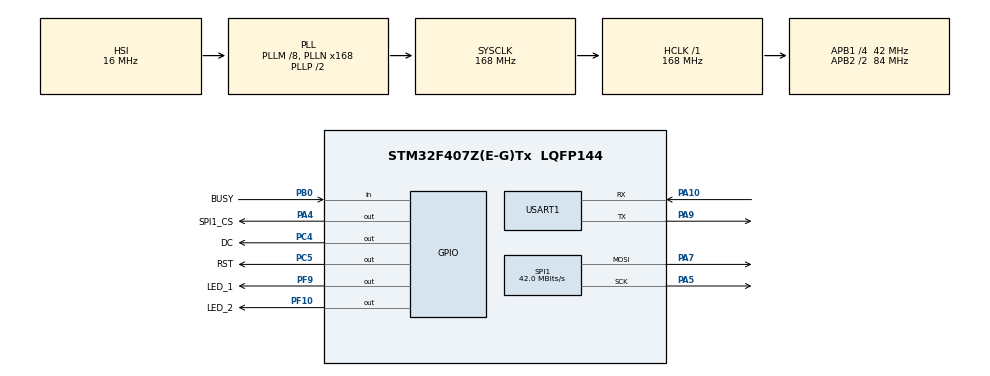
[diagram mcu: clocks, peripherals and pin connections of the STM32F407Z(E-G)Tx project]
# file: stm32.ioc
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Mcu.Family=STM32F4
Mcu.Name=STM32F407Z(E-G)Tx
Mcu.Package=LQFP144
NVIC.PriorityGroup=NVIC_PRIORITYGROUP_4
PA10.Mode=Asynchronous
PA10.Signal=USART1_RX
PA13.Mode=Serial_Wire
PA13.Signal=SYS_JTMS-SWDIO
PA14.Mode=Serial_Wire
PA14.Signal=SYS_JTCK-SWCLK
PA4.GPIO_Label=SPI1_CS
PA4.GPIO_PuPd=GPIO_PULLDOWN
PA4.GPIO_Speed=GPIO_SPEED_FREQ_VERY_HIGH
PA4.Signal=GPIO_Output
PA5.Mode=TX_Only_Simplex_Unidirect_Master
PA5.Signal=SPI1_SCK
PA7.Mode=TX_Only_Simplex_Unidirect_Master
PA7.Signal=SPI1_MOSI
PA9.Mode=Asynchronous
PA9.Signal=USART1_TX
PB0.GPIO_Label=BUSY
PB0.Signal=GPIO_Input
PC14-OSC32_IN.Mode=LSE-External-Oscillator
PC14-OSC32_IN.Signal=RCC_OSC32_IN
PC15-OSC32_OUT.Mode=LSE-External-Oscillator
PC15-OSC32_OUT.Signal=RCC_OSC32_OUT
PC4.GPIO_Label=DC
PC4.GPIO_Speed=GPIO_SPEED_FREQ_VERY_HIGH
PC4.Signal=GPIO_Output
PC5.GPIO_Label=RST
PC5.GPIO_PuPd=GPIO_PULLUP
PC5.GPIO_Speed=GPIO_SPEED_FREQ_VERY_HIGH
PC5.Signal=GPIO_Output
PF10.GPIO_Label=LED_2
PF10.GPIO_PuPd=GPIO_NOPULL
PF10.GPIO_Speed=GPIO_SPEED_FREQ_LOW
PF10.PinState=GPIO_PIN_SET
PF10.Signal=GPIO_Output
PF9.GPIO_Label=LED_1
PF9.GPIO_PuPd=GPIO_NOPULL
PF9.GPIO_Speed=GPIO_SPEED_FREQ_LOW
PF9.Signal=GPIO_Output
PH0-OSC_IN.Mode=HSE-External-Oscillator
PH0-OSC_IN.Signal=RCC_OSC_IN
PH1-OSC_OUT.Mode=HSE-External-Oscillator
PH1-OSC_OUT.Signal=RCC_OSC_OUT
ProjectManager.HeapSize=0x9000
ProjectManager.StackSize=0x1000
ProjectManager.TargetToolchain=EWARM V8.32
RCC.48MHZClocksFreq_Value=84000000
RCC.AHBFreq_Value=168000000
RCC.APB1CLKDivider=RCC_HCLK_DIV4
RCC.APB1Freq_Value=42000000
RCC.APB1TimFreq_Value=84000000
RCC.APB2CLKDivider=RCC_HCLK_DIV2
RCC.APB2Freq_Value=84000000
RCC.APB2TimFreq_Value=168000000
RCC.CortexFreq_Value=168000000
RCC.HCLKFreq_Value=168000000
RCC.HSE_VALUE=8000000
RCC.HSI_VALUE=16000000
RCC.PLLM=8
RCC.PLLN=168
RCC.SYSCLKFreq_VALUE=168000000
RCC.SYSCLKSource=RCC_SYSCLKSOURCE_PLLCLK
RCC.VCOOutputFreq_Value=336000000
SPI1.CalculateBaudRate=42.0 MBits/s
SPI1.Direction=SPI_DIRECTION_2LINES
SPI1.Mode=SPI_MODE_MASTER
SPI1.VirtualType=VM_MASTER
USART1.VirtualMode=VM_ASYNC
board=custom

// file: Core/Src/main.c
/* USER CODE BEGIN Header */
/**
  ******************************************************************************
  * @file           : main.c
  * @brief          : Main program body
  ******************************************************************************
  * @attention
  *
  * Copyright (c) 2023 STMicroelectronics.
  * All rights reserved.
  *
  * This software is licensed under terms that can be found in the LICENSE file
  * in the root directory of this software component.
  * If no LICENSE file comes with this software, it is provided AS-IS.
  *
  ******************************************************************************
  */
/* USER CODE END Header */
#include "main.h"
#include "spi.h"
#include "usart.h"
#include "gpio.h"

/* USER CODE BEGIN Includes */
#include "stdio.h"
#include "EPD_Test.h"
/* USER CODE END Includes */

void SystemClock_Config(void);

int main(void)
{

  /* MCU Configuration--------------------------------------------------------*/

  /* Reset of all peripherals, Initializes the Flash interface and the Systick. */
  HAL_Init();

  /* Configure the system clock */
  SystemClock_Config();

  /* Initialize all configured peripherals */
  MX_GPIO_Init();
  MX_SPI1_Init();
  MX_USART1_UART_Init();
  /* USER CODE BEGIN 2 */

  //EPD_1in02d_test();
  EPD_1in54_test();
  //EPD_1in54_V2_test();
  //EPD_1in54b_test();
  //EPD_1in54b_V2_test();
  //EPD_1in54c_test();
  //EPD_1in64g_test();
  //EPD_2in7_test();
  //EPD_2in7_V2_test();
  //EPD_2IN7b_test();
  //EPD_2in7b_V2_test();
  //EPD_2in9_test();
  //EPD_2in9_V2_test();
  //EPD_2IN9B_V3_test();
  //EPD_2IN9BC_test();
  //EPD_2in9d_test();
  //EPD_2in13_test();
  //EPD_2IN13_V2_test();
  //EPD_2in13_V3_test();
  //EPD_2IN13B_V3_test();
  //EPD_2in13b_V4_test();
  //EPD_2IN13BC_test();
  //EPD_2in13d_test();
  //EPD_2in36g_test();
  //EPD_2in66_test();
  //EPD_2in66b_test();
  //EPD_3in0g_test();
  //EPD_3in7_test();
  //EPD_3in52_test();
  //EPD_4IN01F_test();
  //EPD_4in2_test();
  //EPD_4in2b_V2_test();
  //EPD_4in2bc_test();
  //EPD_4in37g_test();
  //EPD_5in65f_test();
  //EPD_5in83_test();
  //EPD_5in83_V2_test();
  //EPD_5in83b_V2_test();
  //EPD_5in83bc_test();
  //EPD_7in3f_test();
  //EPD_7in3g_test();
  //EPD_7in5_HD_test();
  //EPD_7in5_test();
  //EPD_7in5_V2_test();
  //EPD_7in5b_HD_test();
  //EPD_7in5b_V2_test();
  //EPD_7in5bc_test();

  /* USER CODE END 2 */

  /* Infinite loop */
  /* USER CODE BEGIN WHILE */

  while (1)
  {
    HAL_Delay(10000);
    /* USER CODE END WHILE */

  }
}

void SystemClock_Config(void)
{
  RCC_OscInitTypeDef RCC_OscInitStruct = {0};
  RCC_ClkInitTypeDef RCC_ClkInitStruct = {0};

  /** Configure the main internal regulator output voltage
  */
  __HAL_RCC_PWR_CLK_ENABLE();
  __HAL_PWR_VOLTAGESCALING_CONFIG(PWR_REGULATOR_VOLTAGE_SCALE1);

  /** Initializes the RCC Oscillators according to the specified parameters
  * in the RCC_OscInitTypeDef structure.
  */
  RCC_OscInitStruct.OscillatorType = RCC_OSCILLATORTYPE_HSI;
  RCC_OscInitStruct.HSIState = RCC_HSI_ON;
  RCC_OscInitStruct.HSICalibrationValue = RCC_HSICALIBRATION_DEFAULT;
  RCC_OscInitStruct.PLL.PLLState = RCC_PLL_ON;
  RCC_OscInitStruct.PLL.PLLSource = RCC_PLLSOURCE_HSI;
  RCC_OscInitStruct.PLL.PLLM = 8;
  RCC_OscInitStruct.PLL.PLLN = 168;
  RCC_OscInitStruct.PLL.PLLP = RCC_PLLP_DIV2;
  RCC_OscInitStruct.PLL.PLLQ = 4;
  if (HAL_RCC_OscConfig(&RCC_OscInitStruct) != HAL_OK)
  {
    Error_Handler();
  }

  /** Initializes the CPU, AHB and APB buses clocks
  */
  RCC_ClkInitStruct.ClockType = RCC_CLOCKTYPE_HCLK|RCC_CLOCKTYPE_SYSCLK
                              |RCC_CLOCKTYPE_PCLK1|RCC_CLOCKTYPE_PCLK2;
  RCC_ClkInitStruct.SYSCLKSource = RCC_SYSCLKSOURCE_PLLCLK;
  RCC_ClkInitStruct.AHBCLKDivider = RCC_SYSCLK_DIV1;
  RCC_ClkInitStruct.APB1CLKDivider = RCC_HCLK_DIV4;
  RCC_ClkInitStruct.APB2CLKDivider = RCC_HCLK_DIV2;

  if (HAL_RCC_ClockConfig(&RCC_ClkInitStruct, FLASH_LATENCY_5) != HAL_OK)
  {
    Error_Handler();
  }
}

void Error_Handler(void)
{
  __disable_irq();
  while (1)
  {
  }
}
